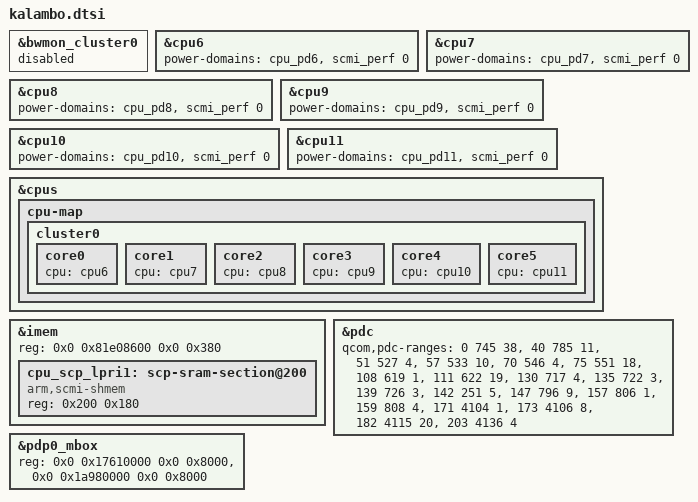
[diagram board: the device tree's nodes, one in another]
// SPDX-License-Identifier: BSD-3-Clause
/*
 * Copyright (c) Qualcomm Technologies, Inc. and/or its subsidiaries.
 */

#include "mahua.dtsi"

/delete-node/ &cluster0_pd;
/delete-node/ &cpu_map;
/delete-node/ &cpu0;
/delete-node/ &cpu1;
/delete-node/ &cpu2;
/delete-node/ &cpu3;
/delete-node/ &cpu4;
/delete-node/ &cpu5;
/delete-node/ &cpu_pd0;
/delete-node/ &cpu_pd1;
/delete-node/ &cpu_pd2;
/delete-node/ &cpu_pd3;
/delete-node/ &cpu_pd4;
/delete-node/ &cpu_pd5;
/delete-node/ &cpu_scp_lpri1;

&bwmon_cluster0 {
	status = "disabled";
};

&cpu6 {
	power-domains = <&cpu_pd6>, <&scmi_perf 0>;
	power-domain-names = "psci", "perf";
};

&cpu7 {
	power-domains = <&cpu_pd7>, <&scmi_perf 0>;
	power-domain-names = "psci", "perf";
};

&cpu8 {
	power-domains = <&cpu_pd8>, <&scmi_perf 0>;
	power-domain-names = "psci", "perf";
};

&cpu9 {
	power-domains = <&cpu_pd9>, <&scmi_perf 0>;
	power-domain-names = "psci", "perf";
};

&cpu10 {
	power-domains = <&cpu_pd10>, <&scmi_perf 0>;
	power-domain-names = "psci", "perf";
};

&cpu11 {
	power-domains = <&cpu_pd11>, <&scmi_perf 0>;
	power-domain-names = "psci", "perf";
};

&cpus {
	cpu-map {
		cluster0 {
			core0 {
				cpu = <&cpu6>;
			};

			core1 {
				cpu = <&cpu7>;
			};

			core2 {
				cpu = <&cpu8>;
			};

			core3 {
				cpu = <&cpu9>;
			};

			core4 {
				cpu = <&cpu10>;
			};

			core5 {
				cpu = <&cpu11>;
			};
		};
	};
};

&imem {
	reg = <0x0 0x81e08600 0x0 0x380>;
	ranges = <0x0 0x0 0x81e08600 0x380>;

	cpu_scp_lpri1: scp-sram-section@200 {
		compatible = "arm,scmi-shmem";
		reg = <0x200 0x180>;
	};
};

&pdc {
	qcom,pdc-ranges = <0 745 38>,
			  <40 785 11>,
			  <51 527 4>,
			  <57 533 10>,
			  <70 546 4>,
			  <75 551 18>,
			  <108 619 1>,
			  <111 622 19>,
			  <130 717 4>,
			  <135 722 3>,
			  <139 726 3>,
			  <142 251 5>,
			  <147 796 9>,
			  <157 806 1>,
			  <159 808 4>,
			  <171 4104 1>,
			  <173 4106 8>,
			  <182 4115 20>,
			  <203 4136 4>;
};

&pdp0_mbox {
	reg = <0x0 0x17610000 0x0 0x8000>,
	      <0x0 0x1a980000 0x0 0x8000>;
};
